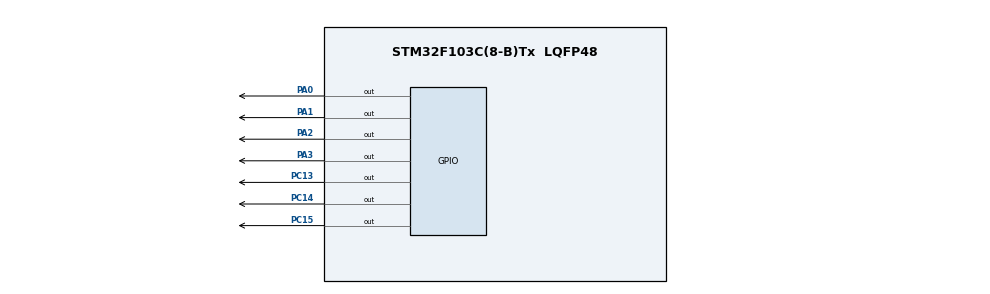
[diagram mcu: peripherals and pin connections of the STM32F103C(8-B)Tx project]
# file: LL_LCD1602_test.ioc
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Mcu.Family=STM32F1
Mcu.Name=STM32F103C(8-B)Tx
Mcu.Package=LQFP48
NVIC.PriorityGroup=NVIC_PRIORITYGROUP_4
PA0-WKUP.GPIO_PuPd=GPIO_PULLUP
PA0-WKUP.Signal=GPIO_Output
PA1.GPIO_PuPd=GPIO_PULLUP
PA1.Signal=GPIO_Output
PA13.Mode=Serial_Wire
PA13.Signal=SYS_JTMS-SWDIO
PA14.Mode=Serial_Wire
PA14.Signal=SYS_JTCK-SWCLK
PA2.GPIO_PuPd=GPIO_PULLUP
PA2.Signal=GPIO_Output
PA3.GPIO_PuPd=GPIO_PULLUP
PA3.Signal=GPIO_Output
PC13-TAMPER-RTC.GPIO_PuPd=GPIO_PULLUP
PC13-TAMPER-RTC.Signal=GPIO_Output
PC14-OSC32_IN.GPIO_PuPd=GPIO_PULLUP
PC14-OSC32_IN.Signal=GPIO_Output
PC15-OSC32_OUT.GPIO_PuPd=GPIO_PULLUP
PC15-OSC32_OUT.Signal=GPIO_Output
PD0-OSC_IN.Mode=HSE-External-Oscillator
PD0-OSC_IN.Signal=RCC_OSC_IN
PD1-OSC_OUT.Mode=HSE-External-Oscillator
PD1-OSC_OUT.Signal=RCC_OSC_OUT
ProjectManager.HeapSize=0x200
ProjectManager.StackSize=0x400
ProjectManager.TargetToolchain=MDK-ARM V5
RCC.AHBCLKDivider=RCC_SYSCLK_DIV2
RCC.AHBFreq_Value=36000000
RCC.APB1Freq_Value=36000000
RCC.APB1TimFreq_Value=36000000
RCC.APB2Freq_Value=36000000
RCC.APB2TimFreq_Value=36000000
RCC.HCLKFreq_Value=36000000
RCC.PLLMUL=RCC_PLL_MUL9
RCC.PLLSourceVirtual=RCC_PLLSOURCE_HSE
RCC.SYSCLKFreq_VALUE=72000000
RCC.SYSCLKSource=RCC_SYSCLKSOURCE_PLLCLK
RCC.USBFreq_Value=72000000
TIM3.Period=65535
TIM3.Prescaler=35999
VP_TIM3_VS_ClockSourceINT.Mode=Internal
board=custom

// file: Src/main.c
/* USER CODE BEGIN Header */
/**
  ******************************************************************************
  * @file           : main.c
  * @brief          : Main program body
  ******************************************************************************
  * @attention
  *
  * <h2><center>&copy; Copyright (c) 2019 STMicroelectronics.
  * All rights reserved.</center></h2>
  *
  * This software component is licensed by ST under BSD 3-Clause license,
  * the "License"; You may not use this file except in compliance with the
  * License. You may obtain a copy of the License at:
  *                        opensource.org/licenses/BSD-3-Clause
  *
  ******************************************************************************
  */
/* USER CODE END Header */

#include "main.h"
#include "tim.h"
#include "gpio.h"

/* USER CODE BEGIN Includes */
#include "Delays.h"
#include "hd44780.h"
/* USER CODE END Includes */

void SystemClock_Config(void);

int main(void)
{

  /* MCU Configuration--------------------------------------------------------*/

  /* Reset of all peripherals, Initializes the Flash interface and the Systick. */

  LL_APB2_GRP1_EnableClock(LL_APB2_GRP1_PERIPH_AFIO);
  LL_APB1_GRP1_EnableClock(LL_APB1_GRP1_PERIPH_PWR);

  NVIC_SetPriorityGrouping(NVIC_PRIORITYGROUP_4);

  /* System interrupt init*/

  /** NOJTAG: JTAG-DP Disabled and SW-DP Enabled
  */
  LL_GPIO_AF_Remap_SWJ_NOJTAG();

  /* Configure the system clock */
  SystemClock_Config();

  /* Initialize all configured peripherals */
  MX_GPIO_Init();
  MX_TIM3_Init();
  /* USER CODE BEGIN 2 */
	//LL_TIM_EnableIT_UPDATE(TIM1);

  /* USER CODE END 2 */

  /* Infinite loop */
  /* USER CODE BEGIN WHILE */

	LCD_Init();
	while (1)
  {

		LED_TOGGLE;
		Delay_us_ms(USEC, 500000);
    /* USER CODE END WHILE */

  }
}

void SystemClock_Config(void)
{
  LL_FLASH_SetLatency(LL_FLASH_LATENCY_2);

   if(LL_FLASH_GetLatency() != LL_FLASH_LATENCY_2)
  {
    Error_Handler();
  }
  LL_RCC_HSE_Enable();

   /* Wait till HSE is ready */
  while(LL_RCC_HSE_IsReady() != 1)
  {

  }
  LL_RCC_PLL_ConfigDomain_SYS(LL_RCC_PLLSOURCE_HSE_DIV_1, LL_RCC_PLL_MUL_9);
  LL_RCC_PLL_Enable();

   /* Wait till PLL is ready */
  while(LL_RCC_PLL_IsReady() != 1)
  {

  }
  LL_RCC_SetAHBPrescaler(LL_RCC_SYSCLK_DIV_2);
  LL_RCC_SetAPB1Prescaler(LL_RCC_APB1_DIV_1);
  LL_RCC_SetAPB2Prescaler(LL_RCC_APB2_DIV_1);
  LL_RCC_SetSysClkSource(LL_RCC_SYS_CLKSOURCE_PLL);

   /* Wait till System clock is ready */
  while(LL_RCC_GetSysClkSource() != LL_RCC_SYS_CLKSOURCE_STATUS_PLL)
  {

  }
  LL_Init1msTick(36000000);
  LL_SYSTICK_SetClkSource(LL_SYSTICK_CLKSOURCE_HCLK);
  LL_SetSystemCoreClock(36000000);
}

void Error_Handler(void)
{
}

/************************ (C) COPYRIGHT STMicroelectronics *****END OF FILE****/
